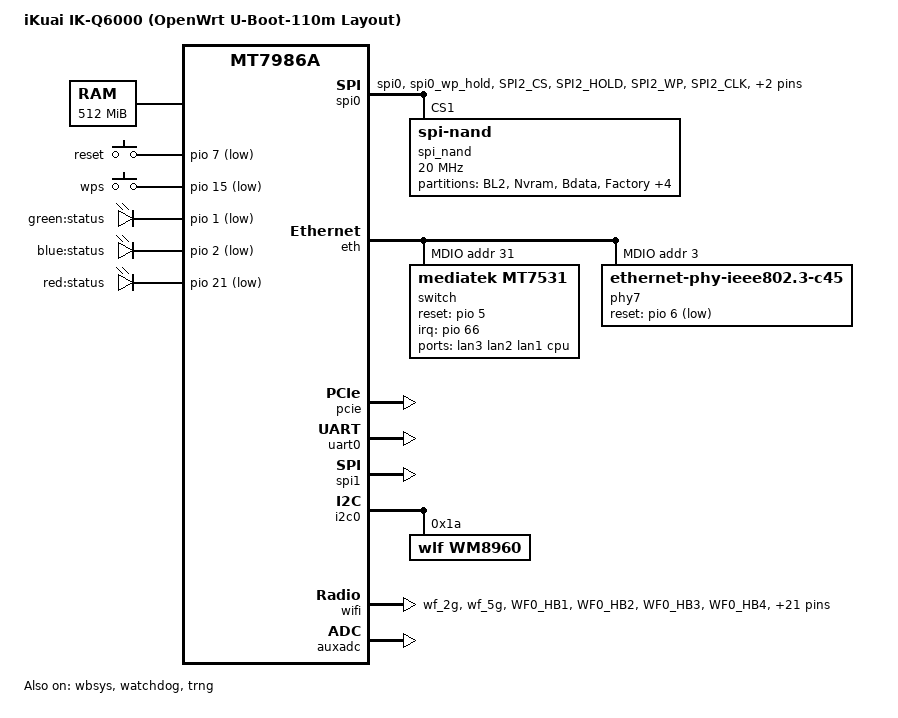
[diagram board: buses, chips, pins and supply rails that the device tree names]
// SPDX-License-Identifier: (GPL-2.0-only OR MIT)
/dts-v1/;

#include <dt-bindings/input/input.h>
#include <dt-bindings/gpio/gpio.h>
#include <dt-bindings/leds/common.h>

#include "mt7986a.dtsi"
#include "mt7986a-pinctrl.dtsi"

/ {
	model = "iKuai IK-Q6000 (OpenWrt U-Boot-110m Layout)";
	compatible = "ikuai,q6000-110m-ubootmod", "mediatek,mt7986a";
	chosen {
		bootargs = "console=ttyS0,115200n1 loglevel=8  \
				earlycon=uart8250,mmio32,0x11002000";
		stdout-path = "serial0:115200n8";
	};

	aliases {
		serial0 = &uart0;
		led-boot = &led_red;
		led-failsafe = &led_red;
		led-running = &led_green;
		led-upgrade = &led_blue;
	};

	memory@40000000 {
		reg = <0 0x40000000 0 0x20000000>;
	};

    gpio-keys {
		compatible = "gpio-keys";

		button-reset {
			label = "reset";
			linux,code = <KEY_RESTART>;
			gpios = <&pio 7 GPIO_ACTIVE_LOW>;
		};

		button-wps {
			label = "wps";
			linux,code = <KEY_WPS_BUTTON>;
			gpios = <&pio 15 GPIO_ACTIVE_LOW>;
		};
	};

	gpio-leds {
		compatible = "gpio-leds";

		led_green: led-0 {
			label = "green:status";
			gpios = <&pio 1 GPIO_ACTIVE_LOW>;
		};

		led_blue: led-1 {
			label = "blue:status";
			gpios = <&pio 2 GPIO_ACTIVE_LOW>;
		};

		led_red: led-2 {
			label = "red:status";
			gpios = <&pio 21 GPIO_ACTIVE_LOW>;
		};
	};
};

&spi0 {
	pinctrl-names = "default";
	pinctrl-0 = <&spi_flash_pins>;
	status = "okay";

	cs-gpios = <0>, <0>;
	spi_nand: spi_nand@0 {
		#address-cells = <1>;
		#size-cells = <1>;
		compatible = "spi-nand";
		reg = <1>;
		spi-max-frequency = <20000000>;
		spi-tx-buswidth = <4>;
		spi-rx-buswidth = <4>;
		mediatek,nmbm;
		mediatek,bmt-max-ratio = <1>;
		mediatek,bmt-max-reserved-blocks = <64>;

		partitions: partitions {
			compatible = "fixed-partitions";
			#address-cells = <1>;
			#size-cells = <1>;

			partition@0 {
				label = "BL2";
				reg = <0x0 0x100000>;
				read-only;
			};

			partition@100000 {
				label = "Nvram";
				reg = <0x100000 0x40000>;
			};

			partition@140000 {
				label = "Bdata";
				reg = <0x140000 0x40000>;
			};

			factory: partition@180000 {
				label = "Factory";
				reg = <0x180000 0x200000>;
				read-only;

				nvmem-layout {
					compatible = "fixed-layout";
					#address-cells = <1>;
					#size-cells = <1>;

					eeprom_factory_0: eeprom@0 {
						reg = <0x0 0x1000>;
					};

					macaddr_factory_10040: macaddr@10040 {
						compatible = "mac-base";
						reg = <0x10040 0x6>;
						#nvmem-cell-cells = <1>;
					};
				};
			};

			partition@380000 {
				label = "FIP";
				reg = <0x380000 0x0200000>;
			};

			partition@580000 {
				label = "crash";
				reg = <0x580000 0x40000>;
				read-only;
			};

			partition@5c0000 {
				label = "crash_log";
				reg = <0x5c0000 0x40000>;
				read-only;
			};

			partition@600000 {
				label = "ubi";
				reg = <0x600000 0x6e00000>;
			};
		};
	};
};

&eth {
	status = "okay";

	gmac0: mac@0 {
		compatible = "mediatek,eth-mac";
		reg = <0>;
		phy-mode = "2500base-x";

		fixed-link {
			speed = <2500>;
			full-duplex;
			pause;
		};
	};

	gmac1: mac@1 {
		compatible = "mediatek,eth-mac";
		reg = <1>;
		phy-mode = "2500base-x";
		phy-handle = <&phy7>

		ext-phy-reg = <3>;
		ext-phy-reset-gpios = <&pio 6 1>;

		fixed-link {
			speed = <2500>;
			full-duplex;
			pause;
		};
	};

	mdio: mdio-bus {
		#address-cells = <1>;
		#size-cells = <0>;
	};
};

&mdio {
	switch: switch@1f {
		compatible = "mediatek,mt7531";
		reg = <31>;
		reset-gpios = <&pio 5 GPIO_ACTIVE_HIGH>;
		interrupt-controller;
		#interrupt-cells = <1>;
		interrupt-parent = <&pio>;
		interrupts = <66 IRQ_TYPE_LEVEL_HIGH>;
	};

	phy7: phy@7 {
		compatible = "ethernet-phy-ieee802.3-c45";
		reg = <3>;
		reset-assert-us = <100000>;
		reset-deassert-us = <100000>;
		reset-gpios = <&pio 6 GPIO_ACTIVE_LOW>;
		realtek,aldps-enable;
	};
};

&switch {
	ports {
		#address-cells = <1>;
		#size-cells = <0>;

		port@2 {
			reg = <2>;
			label = "lan3";
		};

		port@3 {
			reg = <3>;
			label = "lan2";
		};
		
		port@4 {
		        reg = <4>;
		        label = "lan1";
		};

		port@6 {
			compatible = "ethernet-phy-id67c9.de0a"
			reg = <6>;
			label = "cpu";
			phy-mode = "2500base-x";	

			fixed-link {
				speed = <2500>;
				full-duplex;
				pause;
			};
		};
	};
};

&pio {
	spi_flash_pins: spi-flash-pins-33-to-38 {
		mux {
			function = "spi";
			groups = "spi0", "spi0_wp_hold";
		};
		conf-pu {
			pins = "SPI2_CS", "SPI2_HOLD", "SPI2_WP";
			drive-strength = <8>;
			mediatek,pull-up-adv = <0>;
		};
		conf-pd {
			pins = "SPI2_CLK", "SPI2_MOSI", "SPI2_MISO";
			drive-strength = <8>;
			mediatek,pull-down-adv = <0>;
		};
	};

	wf_2g_5g_pins: wf_2g_5g-pins {
		mux {
			function = "wifi";
			groups = "wf_2g", "wf_5g";
		};
		conf {
			pins = "WF0_HB1", "WF0_HB2", "WF0_HB3", "WF0_HB4",
			       "WF0_HB0", "WF0_HB0_B", "WF0_HB5", "WF0_HB6",
			       "WF0_HB7", "WF0_HB8", "WF0_HB9", "WF0_HB10",
			       "WF0_TOP_CLK", "WF0_TOP_DATA", "WF1_HB1",
			       "WF1_HB2", "WF1_HB3", "WF1_HB4", "WF1_HB0",
			       "WF1_HB5", "WF1_HB6", "WF1_HB7", "WF1_HB8",
			       "WF1_TOP_CLK", "WF1_TOP_DATA";
			drive-strength = <4>;
		};
	};

	wf_dbdc_pins: wf_dbdc-pins {
		mux {
			function = "wifi";
			groups = "wf_dbdc";
		};
		conf {
			pins = "WF0_HB1", "WF0_HB2", "WF0_HB3", "WF0_HB4",
			       "WF0_HB0", "WF0_HB0_B", "WF0_HB5", "WF0_HB6",
			       "WF0_HB7", "WF0_HB8", "WF0_HB9", "WF0_HB10",
			       "WF0_TOP_CLK", "WF0_TOP_DATA", "WF1_HB1",
			       "WF1_HB2", "WF1_HB3", "WF1_HB4", "WF1_HB0",
			       "WF1_HB5", "WF1_HB6", "WF1_HB7", "WF1_HB8",
			       "WF1_TOP_CLK", "WF1_TOP_DATA";
			drive-strength = <4>;
		};
	};
};

&pcie {
    pinctrl-names = "default";
    pinctrl-0 = <&pcie0_pins>;
    status = "okay";
};

&uart0 {
    status = "okay";
};

&wbsys {
	status = "okay";
	mediatek,mtd-eeprom = <&factory 0x0000>;
	pinctrl-names = "default", "dbdc";
	pinctrl-0 = <&wf_2g_5g_pins>;
	pinctrl-1 = <&wf_dbdc_pins>;
};

&spi1 {
	pinctrl-names = "default";
	pinctrl-0 = <&spic_pins_g1>;
	status = "okay";
 };

&watchdog {
	status = "okay";
};

&i2c0 {
	pinctrl-names = "default";
	pinctrl-0 = <&i2c_pins>;
	status = "okay";

	wm8960: wm8960@1a {
		compatible = "wlf,wm8960";
		reg = <0x1a>;
	};
};

&trng {
	status = "okay";
};

&wifi {
	status = "okay";
	pinctrl-names = "default";
	pinctrl-0 = <&wf_2g_5g_pins>;
};

&auxadc {
	status = "okay";
};
